# MCXN947_cm33_core0 register map
Vendor: nxp.com; File version: 1.0
CPU: CM33 r2p0, little endian, MPU, FPU, VTOR, 3 interrupt priority bits
Registers are 32-bit, read-write, reset 0x0 unless marked. A register's access mark holds for its fields unless they carry their own. Offsets are from the block's base; [hi:lo] are bit positions.

## USBHS1__USBNC — USBNC
Base 0x4010B200
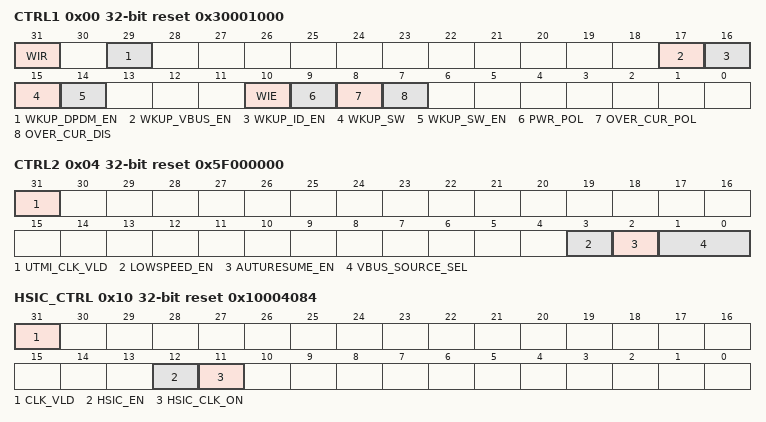
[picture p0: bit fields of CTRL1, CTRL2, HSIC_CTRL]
0x00 CTRL1 reset 0x30001000 — USB OTG Control 1 Register
  [31] WIR ro
    0=NO_WKUP_REQ (No wake-up interrupt request received); 1=WKUP_REQ (Wake-up Interrupt Request received)
  [29] WKUP_DPDM_EN — Wake-up on DPDM change enable
    0=DPDM_WKUP_DIS (DPDM changes wake-up to be disabled only when VBUS is 0.); 1=DPDM_WKUP_EN ((Default) DPDM changes wake-up to be enabled, it is for device only.)
  [17] WKUP_VBUS_EN
    0=WKUP_VBUS_DIS (Disable); 1=WKUP_VBUS_EN (Enable)
  [16] WKUP_ID_EN
    0=WKUP_ID_DIS (Disable); 1=WKUP_ID_EN (Enable)
  [15] WKUP_SW
    0=INACTIVE; 1=FORCE_WKUP (Force wake-up)
  [14] WKUP_SW_EN
    0=SW_WKUP_DIS (Disable); 1=SW_WKUP_EN (Enable)
  [10] WIE
    0=INT_DIS (Interrupt Disabled); 1=INT_EN (Interrupt Enabled)
  [9] PWR_POL
    0=ACTIVE_LO_PMIC (PMIC Power Pin is Low active.); 1=ACTIVE_HI_PMIC (PMIC Power Pin is High active.)
  [8] OVER_CUR_POL
    0=ACTIVE_HI_OVRCRNT (High active (high on this signal represents an overcurrent condition)); 1=ACTIVE_LOW_OVRCRNT (Low active (low on this signal represents an overcurrent condition))
  [7] OVER_CUR_DIS
    0=OVRCRNT_DETCT_EN (Enables overcurrent detection); 1=OVRCRNT_DETCT_DIS (Disables overcurrent detection)
0x04 CTRL2 reset 0x5F000000 — USB OTG Control 2 Register
  [31] UTMI_CLK_VLD write-1-clears
    0=DEFAULT
  [3] LOWSPEED_EN
    0=DEFAULT
  [2] AUTURESUME_EN — Auto Resume Enable
    0=DEFAULT
  [1:0] VBUS_SOURCE_SEL
    0=VBUS_VALID; 1=SESS_VALID_1; 2=SESS_VALID_2; 3=SESS_VALID_3
0x10 HSIC_CTRL reset 0x10004084 — USB Host HSIC Control Register
  [31] CLK_VLD ro
    0=INVALID; 1=VALID
  [12] HSIC_EN
    0=DISABLE (Disabled); 1=ENABLE (Enabled)
  [11] HSIC_CLK_ON
    0=INACTIVE; 1=ACTIVE

## OPAMP0 — OPAMP
Base 0x40110000
Same registers: OPAMP1 0x40113000, OPAMP2 0x40115000
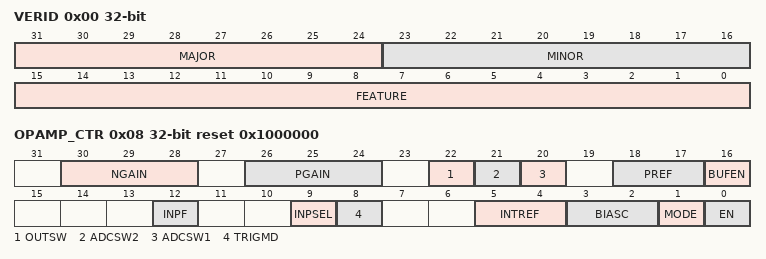
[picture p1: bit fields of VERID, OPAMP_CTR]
0x00 VERID ro — Version ID
  [31:24] MAJOR — Major Version Number
  [23:16] MINOR — Minor Version Number
  [15:0] FEATURE — Feature Specification Number
0x04 PARAM ro reset 0x1 — Parameter
  [0] PGA_FUNCTION — PGA Function Option
    0=CORE_AMP (Core amplifier enabled); 1=PGA (PGA function enabled)
0x08 OPAMP_CTR reset 0x1000000 — OPAMP Control
  [30:28] NGAIN — Negative PGA Selection
    0=BUFFER; 1=G1 (Gain application 1*); 2=G2 (Gain application 2*); 3=G4 (Gain application 4*); 4=G8 (Gain application 8*); 5=G16 (Gain application 16*); 6=G33 (Gain application 33*); 7=G64 (Gain application 64*)
  [26:24] PGAIN — Positive PGA Selection
    0=INP1 (Positive input 1 (INP1)); 1=G2 (Gain application 1*); 2=G3 (Gain application 2*); 3=G5 (Gain application 4*); 4=G9 (Gain application 8*); 5=G17 (Gain application 16*); 6=G34 (Gain application 33*); 7=G65 (Gain application 64*)
  [22] OUTSW — Output Switch
    0=OFF (OPAMP out to negative gain resistor ladder switch off); 1=ON (OPAMP out to negative gain resistor ladder switch on)
  [21] ADCSW2 — Measure Switch 2
    0=DISABLE (Measure positive gain resistor ladder reference voltage switch off); 1=ENABLE (Measure positive gain resistor ladder reference voltage switch on)
  [20] ADCSW1 — Measure Switch 1
    0=OFF (Measure negative gain resistor ladder voltage switch off); 1=ON (Measure negative gain resistor ladder voltage switch on)
  [18:17] PREF — Positive Reference Voltage Selection
    0=DACx_OUT; 1=VDDA/2; 2=VREFO; 3=520 mV
  [16] BUFEN — Reference Buffer
    0=DISABLE (Disables); 1=ENABLE (Enables)
  [12] INPF ro — Positive Input Connection Status
    0=INP0 (Positive input 0 (INP0)); 1=INP1 (Positive input 1 (INP1))
  [9] INPSEL — Positive Input Channel Selection
    0=INP0 (When OPAMP is not in trigger mode, select positive input 0 (INP0)); 1=INP1 (When OPAMP is not in trigger mode, select positive input 1 (INP1))
  [8] TRIGMD — Trigger Mode
    0=DISABLE; 1=ENABLE
  [5:4] INTREF — Internal Reference Voltage Selection
    0=VDDA2 (Select VDDA/2); 1=VDDA3V (Select VDDA_3V); 2=VSSA3V (Select VSSA_3V); 3=NOT (Not allowed)
  [3:2] BIASC — Bias Current Trim Selection
    0=DEF (Default); 1=INC (Increase current); 2=DEC (Decrease current); 3=FUR_DEC (Further decrease current)
  [1] MODE — Mode Selection
    0=LOW (High performance mode); 1=HIGH (Low power mode)
  [0] EN — OPAMP Enable
    0=DISABLE; 1=ENABLE
